# MM32W3xx register map
Vendor: MindMotion Ltd.; Series: MM32W3; File version: 1.4
CPU: CM3 r1p1, little endian, no MPU, no FPU, 4 interrupt priority bits
Registers are 32-bit, read-write, reset 0x0 unless marked. A register's access mark holds for its fields unless they carry their own. Offsets are from the block's base; [hi:lo] are bit positions; {n}, {i} and the like mark numbered series.

## TIM1 — Advanced timer
Base 0x40012C00
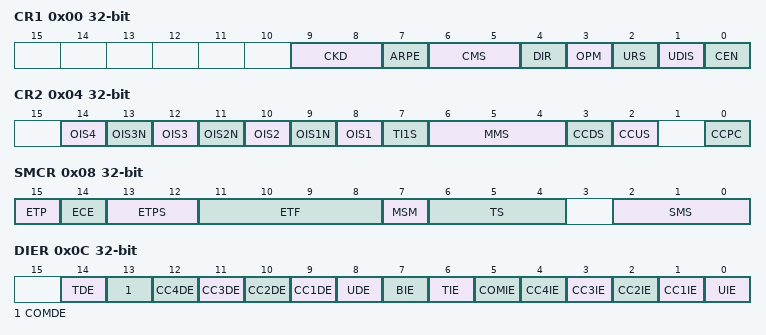
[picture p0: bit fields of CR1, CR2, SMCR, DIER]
0x00 CR1
  [9:8] CKD — Clock division
  [7] ARPE — Auto-reload preload enable
  [6:5] CMS — Center-aligned mode selection
  [4] DIR — Direction
  [3] OPM — One pulse mode
  [2] URS — Update request source
  [1] UDIS — Update disable
  [0] CEN — Counter enable
0x04 CR2
  [14] OIS4
  [13] OIS3N
  [12] OIS3
  [11] OIS2N
  [10] OIS2
  [9] OIS1N — Output Idle state 1
  [8] OIS1 — Output Idle state 1
  [7] TI1S — TI1 selection
  [6:4] MMS — Master mode selection
  [3] CCDS — Capture/compare DMA selection
  [2] CCUS — Capture/compare control update selection
  [0] CCPC — Capture/compare preloaded control
0x08 SMCR
  [15] ETP — External trigger polarity
  [14] ECE — External clock enable
  [13:12] ETPS — External trigger prescaler
  [11:8] ETF — External trigger filter
  [7] MSM — Master/slave mode
  [6:4] TS — Trigger selection
  [2:0] SMS — Slave mode selection
0x0C DIER
  [14] TDE — Trigger DMA request enable
  [13] COMDE — COM DMA request enable
  [n+8] CC{n}DE (n=1..4) — Capture/Compare {n} DMA request enable
  [8] UDE — Update DMA request enable
  [7] BIE — Break interrupt enable
  [6] TIE — Trigger interrupt enable
  [5] COMIE — COM interrupt enable
  [n] CC{n}IE (n=1..4) — Capture/Compare {n} interrupt enable
  [0] UIE — Update interrupt enable
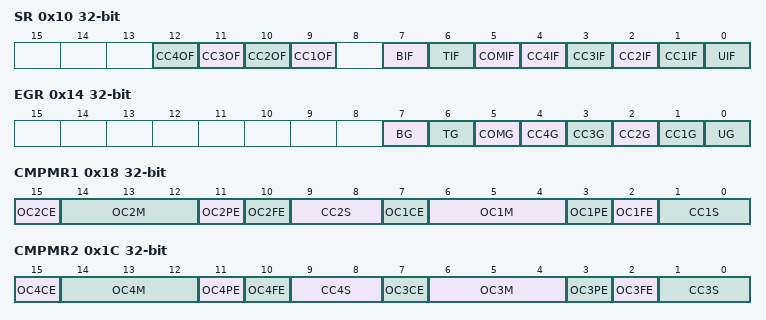
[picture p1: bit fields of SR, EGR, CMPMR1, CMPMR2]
0x10 SR
  [n+8] CC{n}OF (n=1..4) — Capture/Compare {n} overcapture flag
  [7] BIF — Break interrupt flag
  [6] TIF — Trigger interrupt flag
  [5] COMIF — COM interrupt flag
  [n] CC{n}IF (n=1..4) — Capture/Compare {n} interrupt flag
  [0] UIF — Update interrupt flag
0x14 EGR wo
  [7] BG — Break generation
  [6] TG — Trigger generation
  [5] COMG — Capture/Compare control update generation
  [n] CC{n}G (n=1..4) — Capture/Compare {n} generation
  [0] UG — Update generation
0x18 CMPMR1
  [15] OC2CE — Output compare 2 clear enable
  [14:12] OC2M — Output compare 2 mode
  [11] OC2PE — Output compare 2 preload enable
  [10] OC2FE — Output compare 4 fast enable
  [9:8] CC2S — Capture/Compare 2 selection
  [7] OC1CE — Output compare 1 clear enable
  [6:4] OC1M — Output compare 1 mode
  [3] OC1PE — Output compare 1 preload enable
  [2] OC1FE — Output compare 1 fast enable
  [1:0] CC1S — Capture/Compare 1 selection
0x1C CMPMR2
  [15] OC4CE — Output compare 4 clear enable
  [14:12] OC4M — Output compare 4 mode
  [11] OC4PE — Output compare 4 preload enable
  [10] OC4FE — Output compare 4 fast enable
  [9:8] CC4S — Capture/Compare 4 selection
  [7] OC3CE — Output compare 3 clear enable
  [6:4] OC3M — Output compare 3 mode
  [3] OC3PE — Output compare 3 preload enable
  [2] OC3FE — Output compare 3 fast enable
  [1:0] CC3S — Capture/Compare 3 selection
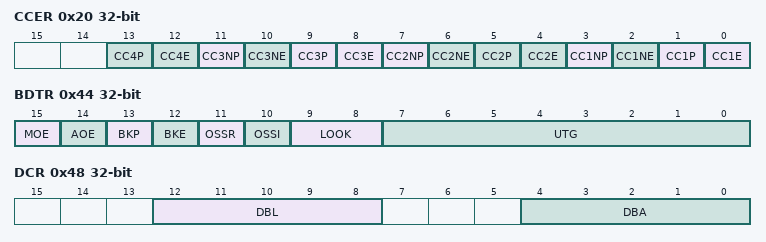
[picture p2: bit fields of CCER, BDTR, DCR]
0x20 CCER
  [4n-3] CC{n}P (n=1..4) — Capture/Compare {n} output polarity
  [4n-4] CC{n}E (n=1..4) — Capture/Compare {n} output enable
  [11] CC3NP — Capture/Compare 3 complementary output polarity
  [10] CC3NE — Capture/Compare 3 complementary output enable
  [7] CC2NP — Capture/Compare 2 complementary output polarity
  [6] CC2NE — Capture/Compare 2 complementary output enable
  [3] CC1NP — Capture/Compare 1 complementary output polarity
  [2] CC1NE — Capture/Compare 1 complementary output enable
0x24 CNT
  [15:0] CNT — Counter value
0x28 PSC
  [15:0] PSC — Prescaler value
0x2C ARR
  [15:0] ARR — Prescaler value
0x30 RCR
  [7:0] REP — Repetition counter value
{0x30+4i} CCR{i} (i=1..4)
  [15:0] CCR{i} — Capture/Compare {i} value
0x44 BDTR
  [15] MOE — Main output enable
  [14] AOE — Automatic output enable
  [13] BKP — Break polarity
  [12] BKE — Break enable
  [11] OSSR — Off-state selection for Run mode
  [10] OSSI — Off-state selection for Idle mode
  [9:8] LOOK — Lock configuration
  [7:0] UTG — Dead-time generator setup
0x48 DCR
  [12:8] DBL — DMA burst length
  [4:0] DBA — DMA base address
0x4C DMAR
  [15:0] DMAB — DMA register for burst accesses

## TIM2 — General purpose timer
Base 0x40000000
Same registers: TIM3 0x40000400, TIM4 0x40000800
Registers as TIM1, without RCR, BDTR; these are added or differ:
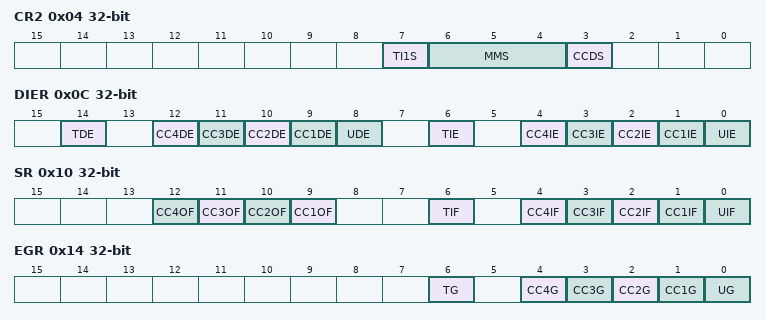
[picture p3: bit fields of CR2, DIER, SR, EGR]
0x04 CR2
  [7] TI1S — TI1 selection
  [6:4] MMS — Master mode selection
  [3] CCDS — Capture/Compare DMA selection
0x0C DIER
  [14] TDE — Trigger DMA request enable
  [n+8] CC{n}DE (n=1..4) — Capture/Compare {n} DMA request enable
  [8] UDE — Update DMA request enable
  [6] TIE — Trigger interrupt enable
  [n] CC{n}IE (n=1..4) — Capture/Compare {n} interrupt enable
  [0] UIE — Update interrupt enable
0x10 SR
  [n+8] CC{n}OF (n=1..4) — Capture/Compare {n} overcapture flag
  [6] TIF — Trigger interrupt flag
  [n] CC{n}IF (n=1..4) — Capture/Compare {n} interrupt flag
  [0] UIF — Update interrupt flag
0x14 EGR wo
  [6] TG — Trigger generation
  [n] CC{n}G (n=1..4) — Capture/compare {n} generation
  [0] UG — Update generation
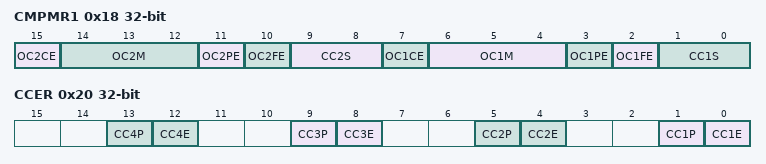
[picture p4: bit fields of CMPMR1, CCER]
0x18 CMPMR1
  [15] OC2CE — Output compare 2 clear enable
  [14:12] OC2M — Output compare 2 mode
  [11] OC2PE — Output compare 2 preload enable
  [10] OC2FE — Output compare 2 fast enable
  [9:8] CC2S — Capture/Compare 2 selection
  [7] OC1CE — Output compare 1 clear enable
  [6:4] OC1M — Output compare 1 enable
  [3] OC1PE — Output compare 1 preload enable
  [2] OC1FE — Output compare 1 fast enable
  [1:0] CC1S — Capture/Compare 1 selection
0x20 CCER
  [4n-3] CC{n}P (n=1..4) — Capture/Compare {n} output polarity
  [4n-4] CC{n}E (n=1..4) — Capture/Compare {n} output enable
0x2C ARR
  [15:0] ARR — Auto reload value
